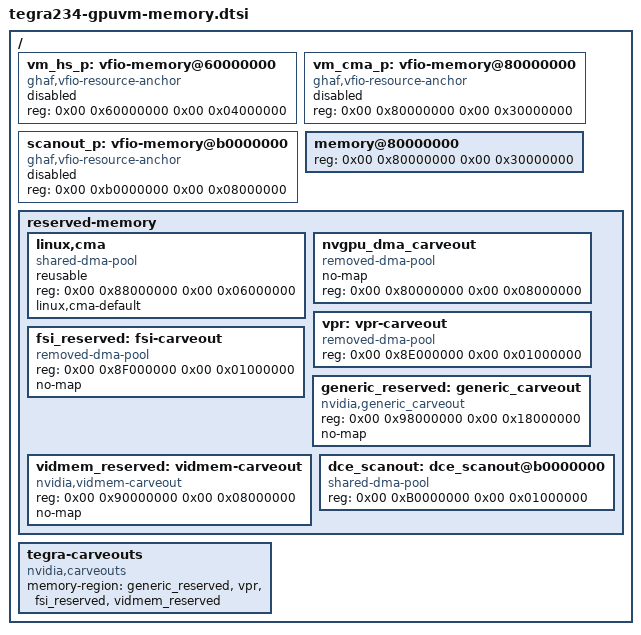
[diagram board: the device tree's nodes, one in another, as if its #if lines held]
// SPDX-License-Identifier: GPL-2.0-only
// SPDX-FileCopyrightText: Copyright (c) 2023, NVIDIA CORPORATION & AFFILIATES.  All rights reserved.
// Guest memory layout: passthrough RAM regions, reserved-memory
// carveouts, and the tegra-carveouts consumer node.

#ifdef GHAF_CROSVM_OVERLAY
/ {
	fragment@10 {
		target-path = "/";
		__overlay__ {
#else
/ {
#endif

#ifdef GHAF_CROSVM_OVERLAY
	// Crosvm maps these VFIO memory backers before guest execution. Keep
	// disabled resource anchors for Crosvm's DT symbol patching; the vm_cma
	// aperture is also described as System RAM below so Linux can initialize
	// its reusable CMA subregion.
	vm_hs_p: vfio-memory@60000000 {
		compatible = "ghaf,vfio-resource-anchor";
		reg = <0x00 0x60000000 0x00 0x04000000>;
		status = "disabled";
	};

	vm_cma_p: vfio-memory@80000000 {
		compatible = "ghaf,vfio-resource-anchor";
		reg = <0x00 0x80000000 0x00 0x30000000>;
		status = "disabled";
	};

	scanout_p: vfio-memory@b0000000 {
		compatible = "ghaf,vfio-resource-anchor";
		reg = <0x00 0xb0000000 0x00 0x08000000>;
		status = "disabled";
	};
#endif

	// The vm_cma VFIO aperture is guest System RAM on both VMMs. Crosvm's main
	// RAM starts above 128GB, so omitting this node leaves linux,cma outside
	// every memory bank and crashes while CMA initializes its page blocks.
	memory@80000000 {
#ifdef EXP_SHRINK_BANK1
		// Concurrent GPU VM (compute-with-host1x): bank1 ends at 0xb0000000, so
		// the guest no longer spans the scanout carveout -> scanout_p is dropped
		// and 0xb0000000 is released to the GUI VM.
		reg = <0x00 0x80000000 0x00 0x30000000>;  // 0x80000000..0xb0000000 (no scanout tail)
#else
		// Keep the scanout VFIO aperture outside System RAM.
		reg = <0x00 0x80000000 0x00 0x30000000>;  // CMA/carveouts; ends before scanout
#endif
		device_type = "memory";
	};

	reserved-memory {
		#address-cells = <2>;
		#size-cells = <2>;
		ranges;

		// 96MB is required by COSMIC's scanout-class buffers.
		linux,cma {
			compatible = "shared-dma-pool";
			reusable;
			reg = <0x00 0x88000000 0x00 0x06000000>; // 96MB
			linux,cma-default;
			status = "okay";
		};

		// Dedicated CMA region for the GPU
		nvgpu_dma_carveout:  nvgpu_dma_carveout{
			compatible = "removed-dma-pool";
			no-map;
			reg = <0x00 0x80000000 0x00 0x08000000>; // 128MB
			status = "okay";
		};

		// Carveout needed by the NVMAP driver
		vpr: vpr-carveout {
			compatible = "removed-dma-pool";
			reg = <0x00 0x8E000000 0x00 0x01000000>; // 16MB (moved from 0x8C for CMA growth)
			status = "okay";
		};

		// Carveout needed by the NVMAP driver
		fsi_reserved: fsi-carveout {
			compatible = "removed-dma-pool";
			reg = <0x00 0x8F000000 0x00 0x01000000>; // 16MB (moved from 0x8D for CMA growth)
			no-map;
			status = "okay";
		};

		// Carveout for GPU VRAM.
		// EXPERIMENT (accel graphics): moved from 4GB@0x100000000 to
		// 256MB@0xA0000000. EGL/nvmap scanout surfaces allocate here, and
		// the display FE's ISO address space is 39-bit: hi-IOVA
		// 0x7f00000000+pa only works for pa < 4GB (0x8000000000 truncates
		// to the in-frame offset -> white screen + smmu_iso faults).
		// 0xA0000000..0xB0000000 is plain guest RAM, 1:1 vfio-backed by
		// vm_cma_p and already inside the anchor's ISO hi map.
		// The former 4GB bank at 0x100000000 had no remaining consumer after
		// this move, so it is no longer declared as guest memory or reserved.
		// (0xA0000000 attempt hung the guest silently; 0xB2000000 sits in
		// the scanout vfio region, untouched by the loader.)
		generic_reserved: generic_carveout {
			compatible = "nvidia,generic_carveout";
			reg = <0x00 0x98000000 0x00 0x18000000>; // 384MB
			// Sizing: EGLStream GBM clients allocate ~3 contiguous frames
			// (3440x1440x4 ~ 21MB each) from this heap, the plane pins the
			// last scanned-out buffer of an exited client, and contiguous
			// carveout allocation fragments across client churn -- 96/112MB
			// proved too small in practice. Covers the former gpu_carveout
			// (unused) plus the plain-RAM stretch 0xA0000000..0xB0000000.
			no-map;
			status = "okay";
		};

		// Carveout needed by the NVMAP driver
		vidmem_reserved: vidmem-carveout {
			compatible = "nvidia,vidmem-carveout";
			reg = <0x00 0x90000000 0x00 0x08000000>; // 128MB
			no-map;
			status = "okay";
		};

		// (gpu_carveout dropped: it sat fully unused at 0x98000000 and
		// its 128MB + the plain-RAM stretch above it were needed to give
		// the generic carveout real headroom.)

		// 1:1 GPA=HPA scanout carveout. nvdisplay allocates the scanout
		// surface here (referenced by the display node's memory-region);
		// patch 0003 forces phys=bus so the host-owned DCE R5 DMAs it at
		// the same physical address. Backed 1:1 by scanout_p in
		// gpu_passthrough_overlay.dts (host removed-dma-pool + vfio
		// mmio-base=0xb0000000), outside every System RAM bank.
/* The display scanout pool is absent from compute-only guests. */
#ifndef EXP_DROP_DISPLAY
		dce_scanout: dce_scanout@b0000000 {
			compatible = "shared-dma-pool";
			// Never lend VFIO-backed scanout pages to movable allocations.
			reg = <0x00 0xB0000000 0x00 0x01000000>; // 16MB; remaining aperture unclaimed
			status = "okay";
		};
#endif
	};

	// Define the carveouts regions for the carveouts driver
	tegra-carveouts {
		compatible = "nvidia,carveouts";
		memory-region = <&generic_reserved &vpr &fsi_reserved &vidmem_reserved>;
		status = "okay";
	};
#ifdef GHAF_CROSVM_OVERLAY
		};
	};
#endif
};
